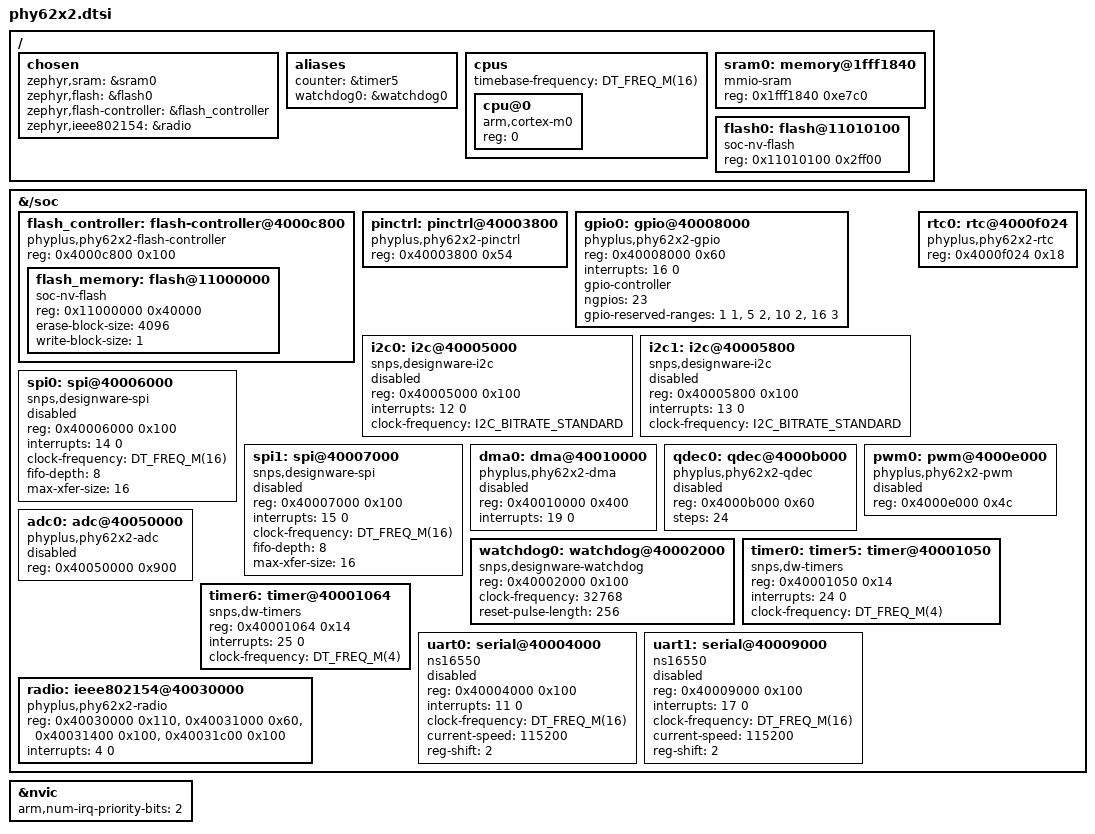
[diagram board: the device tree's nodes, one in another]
/*
 * SPDX-FileCopyrightText: Copyright The Zephyr Project Contributors
 * SPDX-License-Identifier: Apache-2.0
 */

/*
 * The PHY62x2 SoC: a Cortex-M0 with 64 KiB SRAM and the flash on the XIP bus. A board includes this
 * file and gives what differs between modules: the core clock (the CPU timebase-frequency and the
 * clock-frequency of the UARTs), the size of the flash and its partitions, the UART of the console
 * and the pads of the PWM channels. The defaults are those of a 16 MHz core and 256 KiB of flash.
 */

#include <arm/armv6-m.dtsi>
#include <freq.h>
#include <zephyr/dt-bindings/dma/phy62x2-dma.h>
#include <zephyr/dt-bindings/i2c/i2c.h>
#include <zephyr/dt-bindings/pinctrl/phy62x2-pinctrl.h>

/ {
	chosen {
		zephyr,sram = &sram0;
		zephyr,flash = &flash0;
		zephyr,flash-controller = &flash_controller;
		zephyr,ieee802154 = &radio;
	};

	aliases {
		counter = &timer5;
		watchdog0 = &watchdog0;
	};

	cpus {
		#address-cells = <1>;
		#size-cells = <0>;
		timebase-frequency = <DT_FREQ_M(16)>;

		cpu@0 {
			compatible = "arm,cortex-m0";
			reg = <0>;
		};
	};

	/* The first 1 KiB is the interrupt table of the ROM, the rest below 0x1fff1838 is reserved for it */
	sram0: memory@1fff1840 {
		compatible = "mmio-sram";
		reg = <0x1fff1840 0xe7c0>;
	};

	/* The code of the application: a board sets its range, which ends at the storage partition */
	flash0: flash@11010100 {
		compatible = "soc-nv-flash";
		reg = <0x11010100 0x2ff00>;
	};
};

&{/soc} {
	flash_controller: flash-controller@4000c800 {
		compatible = "phyplus,phy62x2-flash-controller";
		reg = <0x4000c800 0x100>;
		#address-cells = <1>;
		#size-cells = <1>;
		status = "okay";

		/* The whole flash, a board sets the size and the partitions */
		flash_memory: flash@11000000 {
			compatible = "soc-nv-flash";
			reg = <0x11000000 0x40000>;
			erase-block-size = <4096>;
			write-block-size = <1>;
		};
	};

	/* The states of the pins are in the board: the pads of a module differ */
	pinctrl: pinctrl@40003800 {
		compatible = "phyplus,phy62x2-pinctrl";
		reg = <0x40003800 0x54>;
		status = "okay";
	};

	gpio0: gpio@40008000 {
		compatible = "phyplus,phy62x2-gpio";
		reg = <0x40008000 0x60>;
		interrupts = <16 0>;
		gpio-controller;
		#gpio-cells = <2>;
		ngpios = <23>;
		gpio-reserved-ranges = <1 1>, <5 2>, <10 2>, <16 3>;
		status = "okay";
	};

	i2c0: i2c@40005000 {
		compatible = "snps,designware-i2c";
		reg = <0x40005000 0x100>;
		interrupts = <12 0>;
		clock-frequency = <I2C_BITRATE_STANDARD>;
		#address-cells = <1>;
		#size-cells = <0>;
		status = "disabled";
	};

	i2c1: i2c@40005800 {
		compatible = "snps,designware-i2c";
		reg = <0x40005800 0x100>;
		interrupts = <13 0>;
		clock-frequency = <I2C_BITRATE_STANDARD>;
		#address-cells = <1>;
		#size-cells = <0>;
		status = "disabled";
	};

	/*
	 * The SPI controllers are DesignWare ones. The depth of the FIFOs is not in the SDK: its
	 * threshold of 4 needs at least 8, which is what is assumed. The clock is the core clock.
	 */
	spi0: spi@40006000 {
		compatible = "snps,designware-spi";
		reg = <0x40006000 0x100>;
		interrupts = <14 0>;
		clock-frequency = <DT_FREQ_M(16)>;
		fifo-depth = <8>;
		max-xfer-size = <16>;
		#address-cells = <1>;
		#size-cells = <0>;
		status = "disabled";
	};

	spi1: spi@40007000 {
		compatible = "snps,designware-spi";
		reg = <0x40007000 0x100>;
		interrupts = <15 0>;
		clock-frequency = <DT_FREQ_M(16)>;
		fifo-depth = <8>;
		max-xfer-size = <16>;
		#address-cells = <1>;
		#size-cells = <0>;
		status = "disabled";
	};

	/* Four channels, the slots of the consumers are PHY62X2_DMA_SLOT_* */
	dma0: dma@40010000 {
		compatible = "phyplus,phy62x2-dma";
		reg = <0x40010000 0x400>;
		interrupts = <19 0>;
		#dma-cells = <2>;
		status = "disabled";
	};

	/* The RTC of the AON block, from RTCCTL; the clock is the 32 kHz RC oscillator */
	rtc0: rtc@4000f024 {
		compatible = "phyplus,phy62x2-rtc";
		reg = <0x4000f024 0x18>;
		status = "okay";
	};

	/* One of the channels X, Y and Z, the pads in the pinctrl state of the board */
	qdec0: qdec@4000b000 {
		compatible = "phyplus,phy62x2-qdec";
		reg = <0x4000b000 0x60>;
		steps = <24>;
		status = "disabled";
	};

	/* Six channels; a board gives the pads of the channels in the pinctrl state */
	pwm0: pwm@4000e000 {
		compatible = "phyplus,phy62x2-pwm";
		reg = <0x4000e000 0x4c>;
		#pwm-cells = <3>;
		status = "disabled";
	};

	/* The inputs are numbered as in the SDK, see the binding; the pads are those of the module */
	adc0: adc@40050000 {
		compatible = "phyplus,phy62x2-adc";
		reg = <0x40050000 0x900>;
		#io-channel-cells = <1>;
		status = "disabled";
	};

	watchdog0: watchdog@40002000 {
		compatible = "snps,designware-watchdog";
		reg = <0x40002000 0x100>;
		/* The RC oscillator of 32 kHz */
		clock-frequency = <32768>;
		/* As in the SDK: a pulse of 256 cycles, a shorter one does not reset the chip */
		reset-pulse-length = <256>;
		status = "okay";
	};

	timer0: timer5: timer@40001050 {
		compatible = "snps,dw-timers";
		reg = <0x40001050 0x14>;
		interrupts = <24 0>;
		clock-frequency = <DT_FREQ_M(4)>;
		status = "okay";
	};

	timer6: timer@40001064 {
		compatible = "snps,dw-timers";
		reg = <0x40001064 0x14>;
		interrupts = <25 0>;
		clock-frequency = <DT_FREQ_M(4)>;
		status = "okay";
	};

	/* The chip has two UARTs; a board enables the one that its console is wired to */
	uart0: serial@40004000 {
		compatible = "ns16550";
		reg = <0x40004000 0x100>;
		interrupts = <11 0>;
		clock-frequency = <DT_FREQ_M(16)>;
		current-speed = <115200>;
		reg-shift = <2>;
		status = "disabled";
	};

	uart1: serial@40009000 {
		compatible = "ns16550";
		reg = <0x40009000 0x100>;
		interrupts = <17 0>;
		clock-frequency = <DT_FREQ_M(16)>;
		current-speed = <115200>;
		reg-shift = <2>;
		status = "disabled";
	};

	radio: ieee802154@40030000 {
		compatible = "phyplus,phy62x2-radio";
		reg = <0x40030000 0x110>, <0x40031000 0x60>,
		      <0x40031400 0x100>, <0x40031c00 0x100>;
		interrupts = <4 0>;
		status = "okay";
	};
};

&nvic {
	arm,num-irq-priority-bits = <2>;
};
